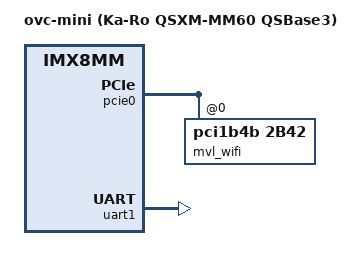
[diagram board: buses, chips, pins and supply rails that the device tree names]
// SPDX-License-Identifier: (GPL-2.0 OR MIT)
/*
 * Copyright (C) 2020 Markus Bauer <MB@KARO-electronics.de>
 *
 */

/dts-v1/;

#include "imx8mm-qsxm-mm60-qsbase3.dts"

/ {
	model = "ovc-mini (Ka-Ro QSXM-MM60 QSBase3)";
};

&pcie0 {
	status = "okay";

	mvl_wifi: wifi@0,0 {
		compatible = "pci1b4b,2b42";
		reg = <0 0 0 0 0>;
		status = "okay";
	};
};

&uart1 { /* BT */
	status = "okay";
};
